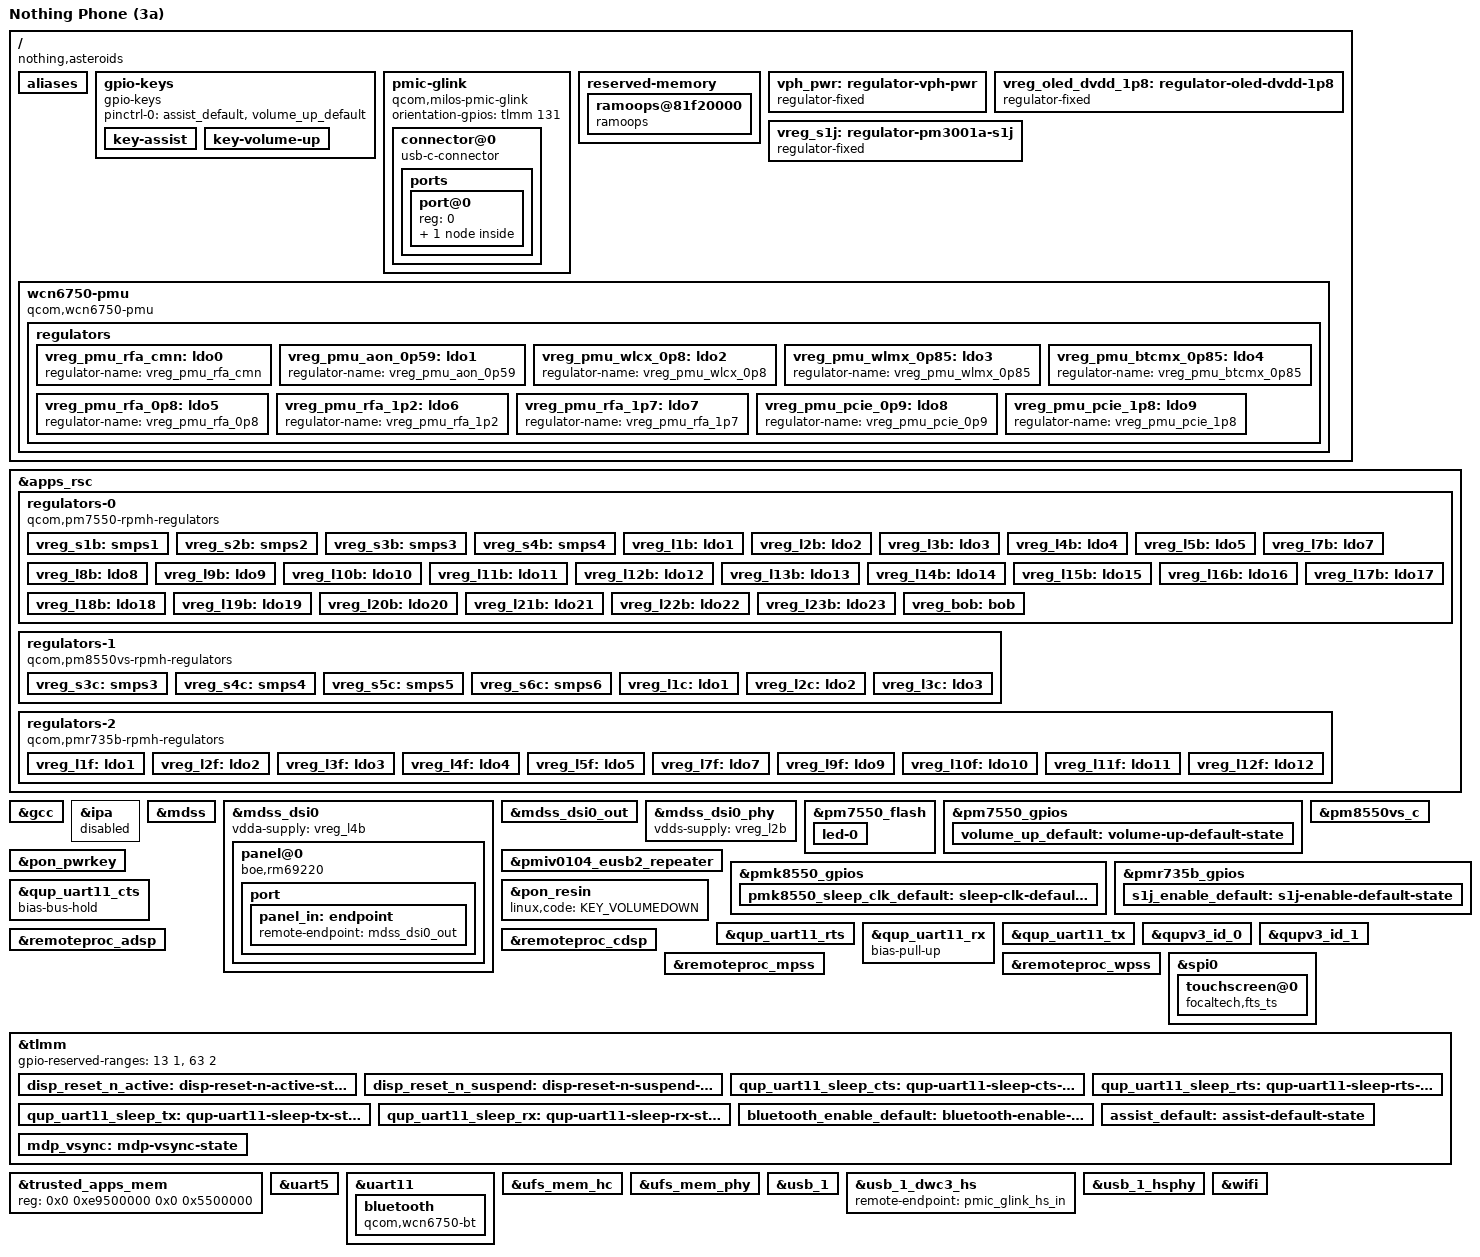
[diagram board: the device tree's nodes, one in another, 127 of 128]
// SPDX-License-Identifier: BSD-3-Clause

/dts-v1/;

#define PMIV0104_SID 7

#include <dt-bindings/arm/qcom,ids.h>
#include <dt-bindings/leds/common.h>
#include <dt-bindings/pinctrl/qcom,pmic-gpio.h>
#include <dt-bindings/regulator/qcom,rpmh-regulator.h>

#include "milos.dtsi"
#include "pm7550.dtsi"
#include "pm8550vs.dtsi"
#include "pmiv0104.dtsi" /* PMIV0102 */
#include "pmk8550.dtsi" /* PMK7635 */
#include "pmr735b.dtsi"

/ {
	model = "Nothing Phone (3a)";
	compatible = "nothing,asteroids", "qcom,milos";
	chassis-type = "handset";
	qcom,board-id = <QCOM_BOARD_ID_QRD 0>;
	qcom,msm-id = <QCOM_ID_SM7635 0x10000>;

	aliases {
		serial0 = &uart5;
		serial1 = &uart11;
	};

	gpio-keys {
		compatible = "gpio-keys";

		pinctrl-0 = <&assist_default>, <&volume_up_default>;
		pinctrl-names = "default";

		key-assist {
			label = "Assistant";
			gpios = <&tlmm 71 GPIO_ACTIVE_LOW>;
			linux,code = <KEY_LEFTMETA>;
			linux,input-type = <EV_KEY>;
		};

		key-volume-up {
			label = "Volume Up";
			gpios = <&pm7550_gpios 6 GPIO_ACTIVE_LOW>;
			linux,code = <KEY_VOLUMEUP>;
		};
	};

	pmic-glink {
		compatible = "qcom,milos-pmic-glink",
			     "qcom,sm8550-pmic-glink",
			     "qcom,pmic-glink";
		#address-cells = <1>;
		#size-cells = <0>;
		orientation-gpios = <&tlmm 131 GPIO_ACTIVE_HIGH>;

		connector@0 {
			compatible = "usb-c-connector";
			reg = <0>;

			power-role = "dual";
			data-role = "dual";

			ports {
				#address-cells = <1>;
				#size-cells = <0>;

				port@0 {
					reg = <0>;

					pmic_glink_hs_in: endpoint {
						remote-endpoint = <&usb_1_dwc3_hs>;
					};
				};
			};
		};
	};

	reserved-memory {
		#address-cells = <2>;
		#size-cells = <2>;
		ranges;

		ramoops@81f20000 {
			compatible = "ramoops";
			reg = <0x0 0x81f20000 0x0 0x400000>;
			console-size = <0x200000>;
			pmsg-size = <0x200000>;
			mem-type = <2>;
		};
	};

	vph_pwr: regulator-vph-pwr {
		compatible = "regulator-fixed";

		regulator-name = "vph_pwr";
		regulator-min-microvolt = <3700000>;
		regulator-max-microvolt = <3700000>;

		regulator-always-on;
		regulator-boot-on;
	};

	vreg_oled_dvdd_1p8: regulator-oled-dvdd-1p8 {
		compatible = "regulator-fixed";

		regulator-name = "oled_dvdd_1p8";
		regulator-min-microvolt = <1800000>;
		regulator-max-microvolt = <1800000>;

		gpio = <&tlmm 109 GPIO_ACTIVE_HIGH>;
		enable-active-high;

		vin-supply = <&vph_pwr>;

		regulator-boot-on;
	};

	vreg_s1j: regulator-pm3001a-s1j {
		compatible = "regulator-fixed";
		regulator-name = "pm3001a_s1j";
		regulator-min-microvolt = <2200000>;
		regulator-max-microvolt = <2200000>;
		startup-delay-us = <1000>;

		gpio = <&pmr735b_gpios 1 GPIO_ACTIVE_HIGH>;
		enable-active-high;

		vin-supply = <&vph_pwr>;

		pinctrl-0 = <&s1j_enable_default>;
		pinctrl-names = "default";
	};

	wcn6750-pmu {
		compatible = "qcom,wcn6750-pmu"; /* WCN6755 */

		vddaon-supply = <&vreg_s3b>;
		vddasd-supply = <&vreg_l7b>;
		vddpmu-supply = <&vreg_s3b>;
		vddrfa0p8-supply = <&vreg_s3b>;
		vddrfa1p2-supply = <&vreg_s2b>;
		vddrfa1p7-supply = <&vreg_s1b>;
		vddrfa2p2-supply = <&vreg_s1j>;

		bt-enable-gpios = <&tlmm 53 GPIO_ACTIVE_HIGH>;

		clocks = <&rpmhcc RPMH_RF_CLK1>;

		pinctrl-0 = <&bluetooth_enable_default>, <&pmk8550_sleep_clk_default>;
		pinctrl-names = "default";

		regulators {
			vreg_pmu_rfa_cmn: ldo0 {
				regulator-name = "vreg_pmu_rfa_cmn";
			};

			vreg_pmu_aon_0p59: ldo1 {
				regulator-name = "vreg_pmu_aon_0p59";
			};

			vreg_pmu_wlcx_0p8: ldo2 {
				regulator-name = "vreg_pmu_wlcx_0p8";
			};

			vreg_pmu_wlmx_0p85: ldo3 {
				regulator-name = "vreg_pmu_wlmx_0p85";
			};

			vreg_pmu_btcmx_0p85: ldo4 {
				regulator-name = "vreg_pmu_btcmx_0p85";
			};

			vreg_pmu_rfa_0p8: ldo5 {
				regulator-name = "vreg_pmu_rfa_0p8";
			};

			vreg_pmu_rfa_1p2: ldo6 {
				regulator-name = "vreg_pmu_rfa_1p2";
			};

			vreg_pmu_rfa_1p7: ldo7 {
				regulator-name = "vreg_pmu_rfa_1p7";
			};

			vreg_pmu_pcie_0p9: ldo8 {
				regulator-name = "vreg_pmu_pcie_0p9";
			};

			vreg_pmu_pcie_1p8: ldo9 {
				regulator-name = "vreg_pmu_pcie_1p8";
			};
		};
	};
};

&apps_rsc {
	regulators-0 {
		compatible = "qcom,pm7550-rpmh-regulators";

		vdd-l1-supply = <&vreg_s1b>;
		vdd-l2-l3-supply = <&vreg_s3b>;
		vdd-l4-l5-supply = <&vreg_s2b>;
		vdd-l7-supply = <&vreg_s1b>;
		vdd-l8-supply = <&vreg_s1b>;
		vdd-l9-l10-supply = <&vreg_s1b>;
		vdd-l11-supply = <&vreg_s1b>;
		vdd-l12-l14-supply = <&vreg_bob>;
		vdd-l13-l16-supply = <&vreg_bob>;
		vdd-l15-l17-l18-l19-l20-l21-l22-l23-supply = <&vreg_bob>;
		vdd-s1-supply = <&vph_pwr>;
		vdd-s2-supply = <&vph_pwr>;
		vdd-s3-supply = <&vph_pwr>;
		vdd-s4-supply = <&vph_pwr>;
		vdd-s5-supply = <&vph_pwr>;
		vdd-s6-supply = <&vph_pwr>;
		vdd-bob-supply = <&vph_pwr>;

		qcom,pmic-id = "b";

		vreg_s1b: smps1 {
			regulator-name = "vreg_s1b";
			regulator-min-microvolt = <1800000>;
			regulator-max-microvolt = <2080000>;
			regulator-initial-mode = <RPMH_REGULATOR_MODE_HPM>;
		};

		vreg_s2b: smps2 {
			regulator-name = "vreg_s2b";
			regulator-min-microvolt = <1256000>;
			regulator-max-microvolt = <1408000>;
			regulator-initial-mode = <RPMH_REGULATOR_MODE_HPM>;
		};

		vreg_s3b: smps3 {
			regulator-name = "vreg_s3b";
			regulator-min-microvolt = <880000>;
			regulator-max-microvolt = <1040000>;
			regulator-initial-mode = <RPMH_REGULATOR_MODE_HPM>;
		};

		vreg_s4b: smps4 {
			regulator-name = "vreg_s4b";
			regulator-min-microvolt = <300000>;
			regulator-max-microvolt = <1004000>;
			regulator-initial-mode = <RPMH_REGULATOR_MODE_HPM>;
		};

		vreg_l1b: ldo1 {
			regulator-name = "vreg_l1b";
			regulator-min-microvolt = <1800000>;
			regulator-max-microvolt = <1800000>;
			regulator-initial-mode = <RPMH_REGULATOR_MODE_HPM>;
		};

		vreg_l2b: ldo2 {
			regulator-name = "vreg_l2b";
			regulator-min-microvolt = <880000>;
			regulator-max-microvolt = <912000>;
			regulator-initial-mode = <RPMH_REGULATOR_MODE_HPM>;
		};

		vreg_l3b: ldo3 {
			regulator-name = "vreg_l3b";
			regulator-min-microvolt = <880000>;
			regulator-max-microvolt = <912000>;
			regulator-initial-mode = <RPMH_REGULATOR_MODE_HPM>;
		};

		vreg_l4b: ldo4 {
			regulator-name = "vreg_l4b";
			regulator-min-microvolt = <1200000>;
			regulator-max-microvolt = <1200000>;
			regulator-initial-mode = <RPMH_REGULATOR_MODE_HPM>;
		};

		vreg_l5b: ldo5 {
			regulator-name = "vreg_l5b";
			regulator-min-microvolt = <1200000>;
			regulator-max-microvolt = <1200000>;
			regulator-initial-mode = <RPMH_REGULATOR_MODE_HPM>;
		};

		vreg_l7b: ldo7 {
			regulator-name = "vreg_l7b";
			regulator-min-microvolt = <1800000>;
			regulator-max-microvolt = <1800000>;
			regulator-initial-mode = <RPMH_REGULATOR_MODE_HPM>;
		};

		vreg_l8b: ldo8 {
			regulator-name = "vreg_l8b";
			regulator-min-microvolt = <1800000>;
			regulator-max-microvolt = <1800000>;
			regulator-initial-mode = <RPMH_REGULATOR_MODE_HPM>;
		};

		vreg_l9b: ldo9 {
			regulator-name = "vreg_l9b";
			regulator-min-microvolt = <1800000>;
			regulator-max-microvolt = <1800000>;
			regulator-initial-mode = <RPMH_REGULATOR_MODE_HPM>;
		};

		vreg_l10b: ldo10 {
			regulator-name = "vreg_l10b";
			regulator-min-microvolt = <1800000>;
			regulator-max-microvolt = <1800000>;
			regulator-initial-mode = <RPMH_REGULATOR_MODE_HPM>;
		};

		vreg_l11b: ldo11 {
			regulator-name = "vreg_l11b";
			regulator-min-microvolt = <1800000>;
			regulator-max-microvolt = <1800000>;
			regulator-initial-mode = <RPMH_REGULATOR_MODE_HPM>;
		};

		vreg_l12b: ldo12 {
			regulator-name = "vreg_l12b";
			/*
			 * Skip voltage voting for UFS VCC, this LDO can support both
			 * UFS 2.2 and UFS 3.1 which require different voltages.
			 */
			regulator-initial-mode = <RPMH_REGULATOR_MODE_HPM>;
		};

		vreg_l13b: ldo13 {
			regulator-name = "vreg_l13b";
			regulator-min-microvolt = <2700000>;
			regulator-max-microvolt = <3300000>;
			regulator-initial-mode = <RPMH_REGULATOR_MODE_HPM>;
		};

		vreg_l14b: ldo14 {
			regulator-name = "vreg_l14b";
			regulator-min-microvolt = <3300000>;
			regulator-max-microvolt = <3304000>;
			regulator-initial-mode = <RPMH_REGULATOR_MODE_HPM>;
		};

		vreg_l15b: ldo15 {
			regulator-name = "vreg_l15b";
			regulator-min-microvolt = <3300000>;
			regulator-max-microvolt = <3304000>;
			regulator-initial-mode = <RPMH_REGULATOR_MODE_HPM>;
		};

		vreg_l16b: ldo16 {
			regulator-name = "vreg_l16b";
			regulator-min-microvolt = <3008000>;
			regulator-max-microvolt = <3008000>;
			regulator-initial-mode = <RPMH_REGULATOR_MODE_HPM>;
		};

		vreg_l17b: ldo17 {
			regulator-name = "vreg_l17b";
			regulator-min-microvolt = <3104000>;
			regulator-max-microvolt = <3104000>;
			regulator-initial-mode = <RPMH_REGULATOR_MODE_HPM>;
		};

		vreg_l18b: ldo18 {
			regulator-name = "vreg_l18b";
			regulator-min-microvolt = <2800000>;
			regulator-max-microvolt = <2800000>;
			regulator-initial-mode = <RPMH_REGULATOR_MODE_HPM>;
		};

		vreg_l19b: ldo19 {
			regulator-name = "vreg_l19b";
			regulator-min-microvolt = <3000000>;
			regulator-max-microvolt = <3000000>;
			regulator-initial-mode = <RPMH_REGULATOR_MODE_HPM>;
		};

		vreg_l20b: ldo20 {
			regulator-name = "vreg_l20b";
			regulator-min-microvolt = <1620000>;
			regulator-max-microvolt = <3544000>;
			regulator-initial-mode = <RPMH_REGULATOR_MODE_HPM>;
		};

		vreg_l21b: ldo21 {
			regulator-name = "vreg_l21b";
			regulator-min-microvolt = <1620000>;
			regulator-max-microvolt = <3544000>;
			regulator-initial-mode = <RPMH_REGULATOR_MODE_HPM>;
		};

		vreg_l22b: ldo22 {
			regulator-name = "vreg_l22b";
			/*
			 * Note about this, Qualcomm sets this to 3.2V downstream for reference
			 * targets and the OEM overrides to 3.3V. However when I try to set
			 * this to 3.3V, it results in RPMH rejecting it.
			 *
			 * Because touchscreen works with it set to 3.2V, just keep the Qualcomm
			 * default.
			 */
			regulator-min-microvolt = <3200000>;
			regulator-max-microvolt = <3200000>;
			regulator-initial-mode = <RPMH_REGULATOR_MODE_HPM>;
		};

		vreg_l23b: ldo23 {
			regulator-name = "vreg_l23b";
			regulator-min-microvolt = <1650000>;
			regulator-max-microvolt = <3544000>;
			regulator-initial-mode = <RPMH_REGULATOR_MODE_HPM>;
		};

		vreg_bob: bob {
			regulator-name = "vreg_bob";
			regulator-min-microvolt = <3008000>;
			regulator-max-microvolt = <3960000>;
			regulator-initial-mode = <RPMH_REGULATOR_MODE_HPM>;
		};
	};

	regulators-1 {
		compatible = "qcom,pm8550vs-rpmh-regulators";

		vdd-l1-supply = <&vreg_s3b>;
		vdd-l2-supply = <&vreg_s3b>;
		vdd-l3-supply = <&vreg_s3b>;
		vdd-s3-supply = <&vph_pwr>;
		vdd-s4-supply = <&vph_pwr>;
		vdd-s5-supply = <&vph_pwr>;
		vdd-s6-supply = <&vph_pwr>;

		qcom,pmic-id = "c";

		vreg_s3c: smps3 {
			regulator-name = "vreg_s3c";
			regulator-min-microvolt = <1010000>;
			regulator-max-microvolt = <1120000>;
			regulator-initial-mode = <RPMH_REGULATOR_MODE_HPM>;
		};

		vreg_s4c: smps4 {
			regulator-name = "vreg_s4c";
			regulator-min-microvolt = <352000>;
			regulator-max-microvolt = <812000>;
			regulator-initial-mode = <RPMH_REGULATOR_MODE_HPM>;
		};

		vreg_s5c: smps5 {
			regulator-name = "vreg_s5c";
			regulator-min-microvolt = <540000>;
			regulator-max-microvolt = <884000>;
			regulator-initial-mode = <RPMH_REGULATOR_MODE_HPM>;
		};

		vreg_s6c: smps6 {
			regulator-name = "vreg_s6c";
			regulator-min-microvolt = <352000>;
			regulator-max-microvolt = <904000>;
			regulator-initial-mode = <RPMH_REGULATOR_MODE_HPM>;
		};

		vreg_l1c: ldo1 {
			regulator-name = "vreg_l1c";
			regulator-min-microvolt = <320000>;
			regulator-max-microvolt = <1004000>;
			regulator-initial-mode = <RPMH_REGULATOR_MODE_HPM>;
		};

		vreg_l2c: ldo2 {
			regulator-name = "vreg_l2c";
			regulator-min-microvolt = <320000>;
			regulator-max-microvolt = <650000>;
			regulator-initial-mode = <RPMH_REGULATOR_MODE_HPM>;
		};

		vreg_l3c: ldo3 {
			regulator-name = "vreg_l3c";
			regulator-min-microvolt = <320000>;
			regulator-max-microvolt = <912000>;
			regulator-initial-mode = <RPMH_REGULATOR_MODE_HPM>;
		};
	};

	regulators-2 {
		compatible = "qcom,pmr735b-rpmh-regulators";

		vdd-l1-l2-supply = <&vreg_s3b>;
		vdd-l3-supply = <&vreg_s3b>;
		vdd-l4-supply = <&vreg_s1b>;
		vdd-l5-supply = <&vreg_s2b>;
		vdd-l7-l8-supply = <&vreg_s2b>;
		vdd-l9-supply = <&vreg_s3b>;
		vdd-l10-supply = <&vreg_s1b>;
		vdd-l11-supply = <&vreg_s3b>;
		vdd-l12-supply = <&vreg_s3b>;

		qcom,pmic-id = "f";

		vreg_l1f: ldo1 {
			regulator-name = "vreg_l1f";
			regulator-min-microvolt = <852000>;
			regulator-max-microvolt = <950000>;
			regulator-initial-mode = <RPMH_REGULATOR_MODE_HPM>;
		};

		vreg_l2f: ldo2 {
			regulator-name = "vreg_l2f";
			regulator-min-microvolt = <751000>;
			regulator-max-microvolt = <824000>;
			regulator-initial-mode = <RPMH_REGULATOR_MODE_HPM>;
		};

		vreg_l3f: ldo3 {
			regulator-name = "vreg_l3f";
			regulator-min-microvolt = <650000>;
			regulator-max-microvolt = <880000>;
			regulator-initial-mode = <RPMH_REGULATOR_MODE_HPM>;
		};

		vreg_l4f: ldo4 {
			regulator-name = "vreg_l4f";
			regulator-min-microvolt = <1700000>;
			regulator-max-microvolt = <1950000>;
			regulator-initial-mode = <RPMH_REGULATOR_MODE_HPM>;
		};

		vreg_l5f: ldo5 {
			regulator-name = "vreg_l5f";
			regulator-min-microvolt = <1140000>;
			regulator-max-microvolt = <1260000>;
			regulator-initial-mode = <RPMH_REGULATOR_MODE_HPM>;
		};

		vreg_l7f: ldo7 {
			regulator-name = "vreg_l7f";
			regulator-min-microvolt = <1080000>;
			regulator-max-microvolt = <1350000>;
			regulator-initial-mode = <RPMH_REGULATOR_MODE_HPM>;
		};

		vreg_l9f: ldo9 {
			regulator-name = "vreg_l9f";
			regulator-min-microvolt = <870000>;
			regulator-max-microvolt = <970000>;
			regulator-initial-mode = <RPMH_REGULATOR_MODE_HPM>;
		};

		vreg_l10f: ldo10 {
			regulator-name = "vreg_l10f";
			regulator-min-microvolt = <1500000>;
			regulator-max-microvolt = <1800000>;
			regulator-initial-mode = <RPMH_REGULATOR_MODE_HPM>;
		};

		vreg_l11f: ldo11 {
			regulator-name = "vreg_l11f";
			regulator-min-microvolt = <320000>;
			regulator-max-microvolt = <864000>;
			regulator-initial-mode = <RPMH_REGULATOR_MODE_HPM>;
		};

		vreg_l12f: ldo12 {
			regulator-name = "vreg_l12f";
			regulator-min-microvolt = <480000>;
			regulator-max-microvolt = <884000>;
			regulator-initial-mode = <RPMH_REGULATOR_MODE_HPM>;
		};
	};
};

&gcc {
	protected-clocks = <GCC_PCIE_1_AUX_CLK>, <GCC_PCIE_1_AUX_CLK_SRC>,
			   <GCC_PCIE_1_CFG_AHB_CLK>, <GCC_PCIE_1_MSTR_AXI_CLK>,
			   <GCC_PCIE_1_PHY_RCHNG_CLK>, <GCC_PCIE_1_PHY_RCHNG_CLK_SRC>,
			   <GCC_PCIE_1_PIPE_CLK>, <GCC_PCIE_1_PIPE_CLK_SRC>,
			   <GCC_PCIE_1_PIPE_DIV2_CLK>, <GCC_PCIE_1_PIPE_DIV2_CLK_SRC>,
			   <GCC_PCIE_1_SLV_AXI_CLK>, <GCC_PCIE_1_SLV_Q2A_AXI_CLK>;
};

&ipa {
	firmware-name = "qcom/milos/nothing/asteroids/ipa_fws.mbn";
	memory-region = <&ipa_fw_mem>;

	qcom,gsi-loader = "self";

	status = "disabled";
};

&mdss {
	status = "okay";
};

&mdss_dsi0 {
	vdda-supply = <&vreg_l4b>;

	status = "okay";

	panel@0 {
		compatible = "boe,rm69220";
		reg = <0>;

		reset-gpios = <&tlmm 12 GPIO_ACTIVE_LOW>;

		vci-supply = <&vreg_l19b>;
		dvdd-supply = <&vreg_oled_dvdd_1p8>;
		vddio-supply = <&vreg_l9b>;

		pinctrl-0 = <&disp_reset_n_active>, <&mdp_vsync>;
		pinctrl-1 = <&disp_reset_n_suspend>, <&mdp_vsync>;
		pinctrl-names = "default", "sleep";

		port {
			panel_in: endpoint {
				remote-endpoint = <&mdss_dsi0_out>;
			};
		};
	};
};

&mdss_dsi0_out {
	data-lanes = <0 1 2 3>;
	remote-endpoint = <&panel_in>;
};

&mdss_dsi0_phy {
	vdds-supply = <&vreg_l2b>;

	status = "okay";
};

&pm7550_flash {
	status = "okay";

	led-0 {
		function = LED_FUNCTION_FLASH;
		color = <LED_COLOR_ID_WHITE>;
		led-sources = <1>, <4>;
		led-max-microamp = <350000>;
		flash-max-microamp = <1500000>;
		flash-max-timeout-us = <400000>;
	};
};

&pm7550_gpios {
	volume_up_default: volume-up-default-state {
		pins = "gpio6";
		function = PMIC_GPIO_FUNC_NORMAL;
		power-source = <1>;
		bias-pull-up;
	};
};

&pm8550vs_c {
	status = "okay";
};

&pmiv0104_eusb2_repeater {
	vdd18-supply = <&vreg_l7b>;
	vdd3-supply = <&vreg_l17b>;

	qcom,tune-res-fsdif = /bits/ 8 <0x5>;
	qcom,tune-usb2-amplitude = /bits/ 8 <0x8>;
	qcom,tune-usb2-disc-thres = /bits/ 8 <0x7>;
	qcom,tune-usb2-preem = /bits/ 8 <0x6>;
};

&pmk8550_gpios {
	pmk8550_sleep_clk_default: sleep-clk-default-state {
		pins = "gpio5";
		function = "func1";
		input-disable;
		output-enable;
		bias-disable;
		power-source = <0>;
	};
};

&pmr735b_gpios {
	s1j_enable_default: s1j-enable-default-state {
		pins = "gpio1";
		function = PMIC_GPIO_FUNC_NORMAL;
		power-source = <0>;
		bias-disable;
		output-low;
	};
};

&pon_pwrkey {
	status = "okay";
};

&pon_resin {
	linux,code = <KEY_VOLUMEDOWN>;

	status = "okay";
};

&qup_uart11_cts {
	/*
	 * Configure a bias-bus-hold on CTS to lower power
	 * usage when Bluetooth is turned off. Bus hold will
	 * maintain a low power state regardless of whether
	 * the Bluetooth module drives the pin in either
	 * direction or leaves the pin fully unpowered.
	 */
	bias-bus-hold;
};

&qup_uart11_rts {
	/* We'll drive RTS, so no pull */
	drive-strength = <2>;
	bias-disable;
};

&qup_uart11_rx {
	/*
	 * Configure a pull-up on RX. This is needed to avoid
	 * garbage data when the TX pin of the Bluetooth module is
	 * in tri-state (module powered off or not driving the
	 * signal yet).
	 */
	bias-pull-up;
};

&qup_uart11_tx {
	/* We'll drive TX, so no pull */
	drive-strength = <2>;
	bias-disable;
};

&qupv3_id_0 {
	status = "okay";
};

&qupv3_id_1 {
	status = "okay";
};

&remoteproc_adsp {
	firmware-name = "qcom/milos/nothing/asteroids/adsp.mbn",
			"qcom/milos/nothing/asteroids/adsp_dtb.mbn";

	status = "okay";
};

&remoteproc_cdsp {
	firmware-name = "qcom/milos/nothing/asteroids/cdsp.mbn",
			"qcom/milos/nothing/asteroids/cdsp_dtb.mbn";

	status = "okay";
};

&remoteproc_mpss {
	firmware-name = "qcom/milos/nothing/asteroids/modem.mbn";

	status = "okay";
};

&remoteproc_wpss {
	firmware-name = "qcom/milos/nothing/asteroids/wpss.mbn";

	status = "okay";
};

&spi0 {
	status = "okay";

	touchscreen@0 {
		compatible = "focaltech,fts_ts";
		reg = <0>;

		vci-supply = <&vreg_l22b>;
		vddio-supply = <&vreg_l11b>;

		interrupt-parent = <&tlmm>;
		interrupts = <19 0x2008>;
		spi-max-frequency = <12000000>;

		focaltech,irq-gpio = <&tlmm 19 0x2008>;
		focaltech,reset-gpio = <&tlmm 20 0x00>;

		focaltech,display-coords = <0 0 1080 2392>;
		focaltech,max-touch-number = <10>;
	};
};

&tlmm {
	gpio-reserved-ranges = <13 1>, /* Display */
			       <63 2>; /* WLAN UART */

	disp_reset_n_active: disp-reset-n-active-state {
		pins = "gpio12";
		function = "gpio";
		drive-strength = <8>;
		bias-disable;
	};

	disp_reset_n_suspend: disp-reset-n-suspend-state {
		pins = "gpio12";
		function = "gpio";
		drive-strength = <2>;
		bias-pull-down;
	};

	qup_uart11_sleep_cts: qup-uart11-sleep-cts-state {
		pins = "gpio48";
		function = "gpio";
		/*
		 * Configure a bias-bus-hold on CTS to lower power
		 * usage when Bluetooth is turned off. Bus hold will
		 * maintain a low power state regardless of whether
		 * the Bluetooth module drives the pin in either
		 * direction or leaves the pin fully unpowered.
		 */
		bias-bus-hold;
	};

	qup_uart11_sleep_rts: qup-uart11-sleep-rts-state {
		pins = "gpio49";
		function = "gpio";
		/*
		 * Configure pull-down on RTS. As RTS is active low
		 * signal, pull it low to indicate the BT SoC that it
		 * can wakeup the system anytime from suspend state by
		 * pulling RX low (by sending wakeup bytes).
		 */
		bias-pull-down;
	};

	qup_uart11_sleep_tx: qup-uart11-sleep-tx-state {
		pins = "gpio50";
		function = "gpio";
		/*
		 * Configure pull-up on TX when it isn't actively driven
		 * to prevent BT SoC from receiving garbage during sleep.
		 */
		bias-pull-up;
	};

	qup_uart11_sleep_rx: qup-uart11-sleep-rx-state {
		pins = "gpio51";
		function = "gpio";
		/*
		 * Configure a pull-up on RX. This is needed to avoid
		 * garbage data when the TX pin of the Bluetooth module
		 * is floating which may cause spurious wakeups.
		 */
		bias-pull-up;
	};

	bluetooth_enable_default: bluetooth-enable-default-state {
		pins = "gpio53";
		function = "gpio";
		output-low;
		bias-disable;
	};

	assist_default: assist-default-state {
		pins = "gpio71";
		function = "gpio";
		bias-pull-up;
	};

	mdp_vsync: mdp-vsync-state {
		pins = "gpio129";
		function = "mdp_vsync";
		drive-strength = <2>;
		bias-pull-down;
	};
};

&trusted_apps_mem {
	reg = <0x0 0xe9500000 0x0 0x5500000>;
};

&uart5 {
	status = "okay";
};

&uart11 {
	/delete-property/ interrupts;
	interrupts-extended = <&intc GIC_SPI 586 IRQ_TYPE_LEVEL_HIGH 0>,
			      <&tlmm 51 IRQ_TYPE_EDGE_FALLING>;

	pinctrl-1 =  <&qup_uart11_sleep_cts>,
		     <&qup_uart11_sleep_rts>,
		     <&qup_uart11_sleep_tx>,
		     <&qup_uart11_sleep_rx>;
	pinctrl-names = "default",
			"sleep";

	status = "okay";

	bluetooth {
		compatible = "qcom,wcn6750-bt"; /* WCN6755 */

		vddrfacmn-supply = <&vreg_pmu_rfa_cmn>;
		vddaon-supply = <&vreg_pmu_aon_0p59>;
		vddbtcmx-supply = <&vreg_pmu_btcmx_0p85>;
		vddrfa0p8-supply = <&vreg_pmu_rfa_0p8>;
		vddrfa1p7-supply = <&vreg_pmu_rfa_1p7>;
		vddrfa1p2-supply = <&vreg_pmu_rfa_1p2>;
	};
};

&ufs_mem_hc {
	reset-gpios = <&tlmm 167 GPIO_ACTIVE_LOW>;

	vcc-supply = <&vreg_l12b>;
	vcc-max-microamp = <800000>;
	vccq2-supply = <&vreg_l4f>;
	vccq2-max-microamp = <750000>;

	status = "okay";
};

&ufs_mem_phy {
	vdda-phy-supply = <&vreg_l2b>;
	vdda-pll-supply = <&vreg_l4b>;

	status = "okay";
};

&usb_1 {
	dr_mode = "otg";

	/* USB 2.0 only, HW does not support USB 3.x */
	qcom,select-utmi-as-pipe-clk;

	status = "okay";
};

&usb_1_dwc3_hs {
	remote-endpoint = <&pmic_glink_hs_in>;
};

&usb_1_hsphy {
	vdd-supply = <&vreg_l2b>;
	vdda12-supply = <&vreg_l4b>;

	phys = <&pmiv0104_eusb2_repeater>;

	status = "okay";
};

&wifi {
	status = "okay";
};
